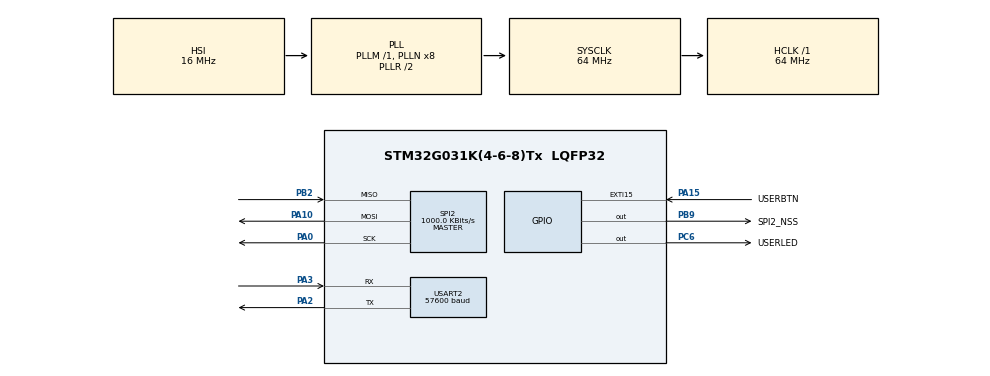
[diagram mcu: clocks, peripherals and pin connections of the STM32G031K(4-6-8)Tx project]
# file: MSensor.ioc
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Mcu.Family=STM32G0
Mcu.Name=STM32G031K(4-6-8)Tx
Mcu.Package=LQFP32
NVIC.EXTI4_15_IRQn=true\:0\:0\:false\:false\:true\:true\:true\:true
NVIC.USART2_IRQn=true\:0\:0\:false\:false\:true\:true\:true\:true
PA0.GPIO_Speed=GPIO_SPEED_FREQ_HIGH
PA0.Mode=Full_Duplex_Master
PA0.PinState=GPIO_PIN_SET
PA0.Signal=SPI2_SCK
PA10.GPIO_Speed=GPIO_SPEED_FREQ_HIGH
PA10.Mode=Full_Duplex_Master
PA10.Signal=SPI2_MOSI
PA15.GPIO_Label=USERBTN
PA15.GPIO_ModeDefaultEXTI=GPIO_MODE_IT_FALLING
PA15.GPIO_PuPd=GPIO_PULLUP
PA15.Signal=GPXTI15
PA2.GPIO_PuPd=GPIO_PULLUP
PA2.Mode=Asynchronous
PA2.PinState=GPIO_PIN_SET
PA2.Signal=USART2_TX
PA3.GPIO_PuPd=GPIO_PULLUP
PA3.Mode=Asynchronous
PA3.Signal=USART2_RX
PB2.GPIO_Speed=GPIO_SPEED_FREQ_HIGH
PB2.Mode=Full_Duplex_Master
PB2.Signal=SPI2_MISO
PB9.GPIO_Label=SPI2_NSS
PB9.PinState=GPIO_PIN_SET
PB9.Signal=GPIO_Output
PC6.GPIO_Label=USERLED
PC6.Signal=GPIO_Output
ProjectManager.HeapSize=0x200
ProjectManager.StackSize=0x400
ProjectManager.TargetToolchain=STM32CubeIDE
RCC.ADCFreq_Value=64000000
RCC.AHBFreq_Value=64000000
RCC.CortexFreq_Value=64000000
RCC.EXTERNAL_CLOCK_VALUE=12288000
RCC.HCLKFreq_Value=64000000
RCC.HSE_VALUE=8000000
RCC.HSI_VALUE=16000000
RCC.LSE_VALUE=32768
RCC.SYSCLKFreq_VALUE=64000000
RCC.SYSCLKSource=RCC_SYSCLKSOURCE_PLLCLK
RCC.VCOOutputFreq_Value=128000000
SPI2.BaudRatePrescaler=SPI_BAUDRATEPRESCALER_64
SPI2.CLKPhase=SPI_PHASE_2EDGE
SPI2.CLKPolarity=SPI_POLARITY_HIGH
SPI2.CalculateBaudRate=1000.0 KBits/s
SPI2.Direction=SPI_DIRECTION_2LINES
SPI2.Mode=SPI_MODE_MASTER
SPI2.VirtualType=VM_MASTER
USART2.BaudRate=57600
USART2.VirtualMode-Asynchronous=VM_ASYNC
board=custom

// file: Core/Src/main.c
/* USER CODE BEGIN Header */
/**
  ******************************************************************************
  * @file           : main.c
  * @brief          : Main program body
  ******************************************************************************
  * @attention
  *
  * Copyright (c) 2024 STMicroelectronics.
  * All rights reserved.
  *
  * This software is licensed under terms that can be found in the LICENSE file
  * in the root directory of this software component.
  * If no LICENSE file comes with this software, it is provided AS-IS.
  *
  ******************************************************************************
  */
/* USER CODE END Header */
#include "main.h"

/* USER CODE BEGIN Includes */
#include "functions.h"
/* USER CODE END Includes */

SPI_HandleTypeDef hspi2;

UART_HandleTypeDef huart2;

/* USER CODE BEGIN PV */
globalVariableType gv = {0};
globalVariableType *pgv = &gv;

/* USER CODE END PV */

void SystemClock_Config(void);
static void MX_GPIO_Init(void);
static void MX_USART2_UART_Init(void);
static void MX_SPI2_Init(void);

int main(void)
{

  /* MCU Configuration--------------------------------------------------------*/

  /* Reset of all peripherals, Initializes the Flash interface and the Systick. */
  HAL_Init();

  /* Configure the system clock */
  SystemClock_Config();

  /* Initialize all configured peripherals */
  MX_GPIO_Init();
  MX_USART2_UART_Init();
  MX_SPI2_Init();
  /* USER CODE BEGIN 2 */
  myDelay(100);
  App_Init();

  /* USER CODE END 2 */

  /* Infinite loop */
  /* USER CODE BEGIN WHILE */
  while (1)
  {
      timedAppTasks();
    /* USER CODE END WHILE */

  }
}

void SystemClock_Config(void)
{
  RCC_OscInitTypeDef RCC_OscInitStruct = {0};
  RCC_ClkInitTypeDef RCC_ClkInitStruct = {0};

  /** Configure the main internal regulator output voltage
  */
  HAL_PWREx_ControlVoltageScaling(PWR_REGULATOR_VOLTAGE_SCALE1);

  /** Initializes the RCC Oscillators according to the specified parameters
  * in the RCC_OscInitTypeDef structure.
  */
  RCC_OscInitStruct.OscillatorType = RCC_OSCILLATORTYPE_HSI;
  RCC_OscInitStruct.HSIState = RCC_HSI_ON;
  RCC_OscInitStruct.HSIDiv = RCC_HSI_DIV1;
  RCC_OscInitStruct.HSICalibrationValue = RCC_HSICALIBRATION_DEFAULT;
  RCC_OscInitStruct.PLL.PLLState = RCC_PLL_ON;
  RCC_OscInitStruct.PLL.PLLSource = RCC_PLLSOURCE_HSI;
  RCC_OscInitStruct.PLL.PLLM = RCC_PLLM_DIV1;
  RCC_OscInitStruct.PLL.PLLN = 8;
  RCC_OscInitStruct.PLL.PLLP = RCC_PLLP_DIV2;
  RCC_OscInitStruct.PLL.PLLQ = RCC_PLLQ_DIV2;
  RCC_OscInitStruct.PLL.PLLR = RCC_PLLR_DIV2;
  if (HAL_RCC_OscConfig(&RCC_OscInitStruct) != HAL_OK)
  {
    Error_Handler();
  }

  /** Initializes the CPU, AHB and APB buses clocks
  */
  RCC_ClkInitStruct.ClockType = RCC_CLOCKTYPE_HCLK|RCC_CLOCKTYPE_SYSCLK
                              |RCC_CLOCKTYPE_PCLK1;
  RCC_ClkInitStruct.SYSCLKSource = RCC_SYSCLKSOURCE_PLLCLK;
  RCC_ClkInitStruct.AHBCLKDivider = RCC_SYSCLK_DIV1;
  RCC_ClkInitStruct.APB1CLKDivider = RCC_HCLK_DIV1;

  if (HAL_RCC_ClockConfig(&RCC_ClkInitStruct, FLASH_LATENCY_2) != HAL_OK)
  {
    Error_Handler();
  }
}

static void MX_SPI2_Init(void)
{

  /* SPI2 parameter configuration*/
  hspi2.Instance = SPI2;
  hspi2.Init.Mode = SPI_MODE_MASTER;
  hspi2.Init.Direction = SPI_DIRECTION_2LINES;
  hspi2.Init.DataSize = SPI_DATASIZE_8BIT;
  hspi2.Init.CLKPolarity = SPI_POLARITY_HIGH;
  hspi2.Init.CLKPhase = SPI_PHASE_2EDGE;
  hspi2.Init.NSS = SPI_NSS_SOFT;
  hspi2.Init.BaudRatePrescaler = SPI_BAUDRATEPRESCALER_64;
  hspi2.Init.FirstBit = SPI_FIRSTBIT_MSB;
  hspi2.Init.TIMode = SPI_TIMODE_DISABLE;
  hspi2.Init.CRCCalculation = SPI_CRCCALCULATION_DISABLE;
  hspi2.Init.CRCPolynomial = 7;
  hspi2.Init.CRCLength = SPI_CRC_LENGTH_DATASIZE;
  hspi2.Init.NSSPMode = SPI_NSS_PULSE_DISABLE;
  if (HAL_SPI_Init(&hspi2) != HAL_OK)
  {
    Error_Handler();
  }

}

static void MX_USART2_UART_Init(void)
{

  huart2.Instance = USART2;
  huart2.Init.BaudRate = 57600;
  huart2.Init.WordLength = UART_WORDLENGTH_8B;
  huart2.Init.StopBits = UART_STOPBITS_1;
  huart2.Init.Parity = UART_PARITY_NONE;
  huart2.Init.Mode = UART_MODE_TX_RX;
  huart2.Init.HwFlowCtl = UART_HWCONTROL_NONE;
  huart2.Init.OverSampling = UART_OVERSAMPLING_16;
  huart2.Init.OneBitSampling = UART_ONE_BIT_SAMPLE_DISABLE;
  huart2.Init.ClockPrescaler = UART_PRESCALER_DIV1;
  huart2.AdvancedInit.AdvFeatureInit = UART_ADVFEATURE_NO_INIT;
  if (HAL_UART_Init(&huart2) != HAL_OK)
  {
    Error_Handler();
  }

}

static void MX_GPIO_Init(void)
{
  GPIO_InitTypeDef GPIO_InitStruct = {0};

  /* GPIO Ports Clock Enable */
  __HAL_RCC_GPIOB_CLK_ENABLE();
  __HAL_RCC_GPIOA_CLK_ENABLE();
  __HAL_RCC_GPIOC_CLK_ENABLE();

  /*Configure GPIO pin Output Level */
  HAL_GPIO_WritePin(SPI2_NSS_GPIO_Port, SPI2_NSS_Pin, GPIO_PIN_SET);

  /*Configure GPIO pin Output Level */
  HAL_GPIO_WritePin(USERLED_GPIO_Port, USERLED_Pin, GPIO_PIN_RESET);

  /*Configure GPIO pin : SPI2_NSS_Pin */
  GPIO_InitStruct.Pin = SPI2_NSS_Pin;
  GPIO_InitStruct.Mode = GPIO_MODE_OUTPUT_PP;
  GPIO_InitStruct.Pull = GPIO_NOPULL;
  GPIO_InitStruct.Speed = GPIO_SPEED_FREQ_LOW;
  HAL_GPIO_Init(SPI2_NSS_GPIO_Port, &GPIO_InitStruct);

  /*Configure GPIO pin : USERLED_Pin */
  GPIO_InitStruct.Pin = USERLED_Pin;
  GPIO_InitStruct.Mode = GPIO_MODE_OUTPUT_PP;
  GPIO_InitStruct.Pull = GPIO_NOPULL;
  GPIO_InitStruct.Speed = GPIO_SPEED_FREQ_LOW;
  HAL_GPIO_Init(USERLED_GPIO_Port, &GPIO_InitStruct);

  /*Configure GPIO pin : USERBTN_Pin */
  GPIO_InitStruct.Pin = USERBTN_Pin;
  GPIO_InitStruct.Mode = GPIO_MODE_IT_FALLING;
  GPIO_InitStruct.Pull = GPIO_PULLUP;
  HAL_GPIO_Init(USERBTN_GPIO_Port, &GPIO_InitStruct);

  /* EXTI interrupt init*/
  HAL_NVIC_SetPriority(EXTI4_15_IRQn, 0, 0);
  HAL_NVIC_EnableIRQ(EXTI4_15_IRQn);

}

void Error_Handler(void)
{
  __disable_irq();
  while (1)
  {
  }
}
